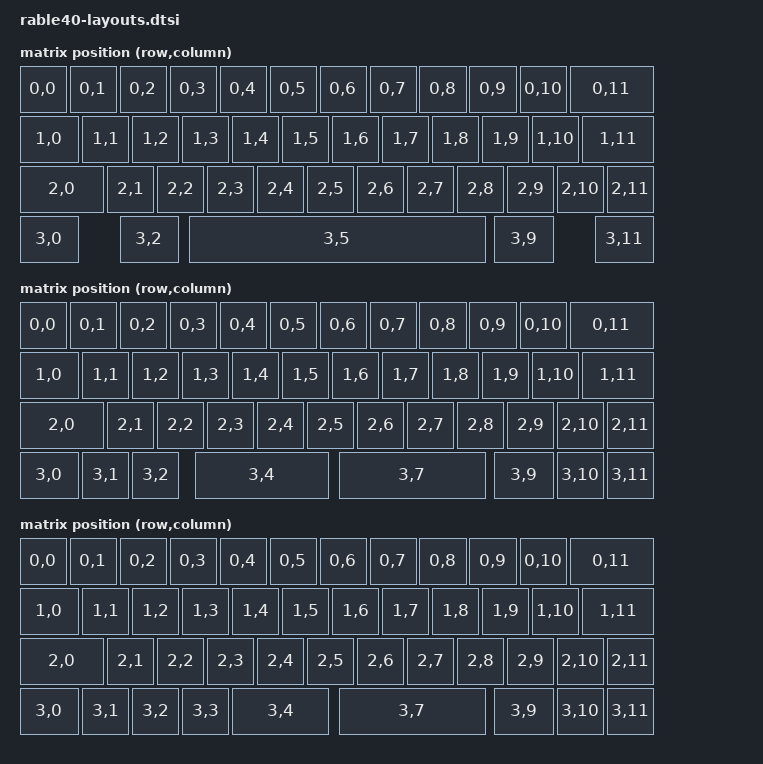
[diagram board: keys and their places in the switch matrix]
/* SPDX-License-Identifier: MIT */
/* Physical bottom-row presets; wiring verified against the supplied Gerbers. */
/ {
    space6_layout: space6_layout {
        compatible = "zmk,physical-layout";
        display-name = "6u spacebar (centered / off-center stem)";
        kscan = <&kscan0>;
        transform = <&space6_transform>;
        keys =
            <&key_physical_attrs 100 100 0 0 0 0 0>,
            <&key_physical_attrs 100 100 100 0 0 0 0>,
            <&key_physical_attrs 100 100 200 0 0 0 0>,
            <&key_physical_attrs 100 100 300 0 0 0 0>,
            <&key_physical_attrs 100 100 400 0 0 0 0>,
            <&key_physical_attrs 100 100 500 0 0 0 0>,
            <&key_physical_attrs 100 100 600 0 0 0 0>,
            <&key_physical_attrs 100 100 700 0 0 0 0>,
            <&key_physical_attrs 100 100 800 0 0 0 0>,
            <&key_physical_attrs 100 100 900 0 0 0 0>,
            <&key_physical_attrs 100 100 1000 0 0 0 0>,
            <&key_physical_attrs 175 100 1100 0 0 0 0>,
            <&key_physical_attrs 125 100 0 100 0 0 0>,
            <&key_physical_attrs 100 100 125 100 0 0 0>,
            <&key_physical_attrs 100 100 225 100 0 0 0>,
            <&key_physical_attrs 100 100 325 100 0 0 0>,
            <&key_physical_attrs 100 100 425 100 0 0 0>,
            <&key_physical_attrs 100 100 525 100 0 0 0>,
            <&key_physical_attrs 100 100 625 100 0 0 0>,
            <&key_physical_attrs 100 100 725 100 0 0 0>,
            <&key_physical_attrs 100 100 825 100 0 0 0>,
            <&key_physical_attrs 100 100 925 100 0 0 0>,
            <&key_physical_attrs 100 100 1025 100 0 0 0>,
            <&key_physical_attrs 150 100 1125 100 0 0 0>,
            <&key_physical_attrs 175 100 0 200 0 0 0>,
            <&key_physical_attrs 100 100 175 200 0 0 0>,
            <&key_physical_attrs 100 100 275 200 0 0 0>,
            <&key_physical_attrs 100 100 375 200 0 0 0>,
            <&key_physical_attrs 100 100 475 200 0 0 0>,
            <&key_physical_attrs 100 100 575 200 0 0 0>,
            <&key_physical_attrs 100 100 675 200 0 0 0>,
            <&key_physical_attrs 100 100 775 200 0 0 0>,
            <&key_physical_attrs 100 100 875 200 0 0 0>,
            <&key_physical_attrs 100 100 975 200 0 0 0>,
            <&key_physical_attrs 100 100 1075 200 0 0 0>,
            <&key_physical_attrs 100 100 1175 200 0 0 0>,
            <&key_physical_attrs 125 100 0 300 0 0 0>,
            <&key_physical_attrs 125 100 200 300 0 0 0>,
            <&key_physical_attrs 600 100 338 300 0 0 0>,
            <&key_physical_attrs 125 100 950 300 0 0 0>,
            <&key_physical_attrs 125 100 1150 300 0 0 0>;
    };
    space6_transform: space6_transform {
        compatible = "zmk,matrix-transform";
        rows = <4>;
        columns = <12>;
        map = <RC(0,0) RC(0,1) RC(0,2) RC(0,3) RC(0,4) RC(0,5) RC(0,6) RC(0,7) RC(0,8) RC(0,9) RC(0,10) RC(0,11) RC(1,0) RC(1,1) RC(1,2) RC(1,3) RC(1,4) RC(1,5) RC(1,6) RC(1,7) RC(1,8) RC(1,9) RC(1,10) RC(1,11) RC(2,0) RC(2,1) RC(2,2) RC(2,3) RC(2,4) RC(2,5) RC(2,6) RC(2,7) RC(2,8) RC(2,9) RC(2,10) RC(2,11) RC(3,0) RC(3,2) RC(3,5) RC(3,9) RC(3,11)>;
    };
    split275_3_layout: split275_3_layout {
        compatible = "zmk,physical-layout";
        display-name = "Split 2.75u + 3u (8 bottom keys)";
        kscan = <&kscan0>;
        transform = <&split275_3_transform>;
        keys =
            <&key_physical_attrs 100 100 0 0 0 0 0>,
            <&key_physical_attrs 100 100 100 0 0 0 0>,
            <&key_physical_attrs 100 100 200 0 0 0 0>,
            <&key_physical_attrs 100 100 300 0 0 0 0>,
            <&key_physical_attrs 100 100 400 0 0 0 0>,
            <&key_physical_attrs 100 100 500 0 0 0 0>,
            <&key_physical_attrs 100 100 600 0 0 0 0>,
            <&key_physical_attrs 100 100 700 0 0 0 0>,
            <&key_physical_attrs 100 100 800 0 0 0 0>,
            <&key_physical_attrs 100 100 900 0 0 0 0>,
            <&key_physical_attrs 100 100 1000 0 0 0 0>,
            <&key_physical_attrs 175 100 1100 0 0 0 0>,
            <&key_physical_attrs 125 100 0 100 0 0 0>,
            <&key_physical_attrs 100 100 125 100 0 0 0>,
            <&key_physical_attrs 100 100 225 100 0 0 0>,
            <&key_physical_attrs 100 100 325 100 0 0 0>,
            <&key_physical_attrs 100 100 425 100 0 0 0>,
            <&key_physical_attrs 100 100 525 100 0 0 0>,
            <&key_physical_attrs 100 100 625 100 0 0 0>,
            <&key_physical_attrs 100 100 725 100 0 0 0>,
            <&key_physical_attrs 100 100 825 100 0 0 0>,
            <&key_physical_attrs 100 100 925 100 0 0 0>,
            <&key_physical_attrs 100 100 1025 100 0 0 0>,
            <&key_physical_attrs 150 100 1125 100 0 0 0>,
            <&key_physical_attrs 175 100 0 200 0 0 0>,
            <&key_physical_attrs 100 100 175 200 0 0 0>,
            <&key_physical_attrs 100 100 275 200 0 0 0>,
            <&key_physical_attrs 100 100 375 200 0 0 0>,
            <&key_physical_attrs 100 100 475 200 0 0 0>,
            <&key_physical_attrs 100 100 575 200 0 0 0>,
            <&key_physical_attrs 100 100 675 200 0 0 0>,
            <&key_physical_attrs 100 100 775 200 0 0 0>,
            <&key_physical_attrs 100 100 875 200 0 0 0>,
            <&key_physical_attrs 100 100 975 200 0 0 0>,
            <&key_physical_attrs 100 100 1075 200 0 0 0>,
            <&key_physical_attrs 100 100 1175 200 0 0 0>,
            <&key_physical_attrs 125 100 0 300 0 0 0>,
            <&key_physical_attrs 100 100 125 300 0 0 0>,
            <&key_physical_attrs 100 100 225 300 0 0 0>,
            <&key_physical_attrs 275 100 350 300 0 0 0>,
            <&key_physical_attrs 300 100 638 300 0 0 0>,
            <&key_physical_attrs 125 100 950 300 0 0 0>,
            <&key_physical_attrs 100 100 1075 300 0 0 0>,
            <&key_physical_attrs 100 100 1175 300 0 0 0>;
    };
    split275_3_transform: split275_3_transform {
        compatible = "zmk,matrix-transform";
        rows = <4>;
        columns = <12>;
        map = <RC(0,0) RC(0,1) RC(0,2) RC(0,3) RC(0,4) RC(0,5) RC(0,6) RC(0,7) RC(0,8) RC(0,9) RC(0,10) RC(0,11) RC(1,0) RC(1,1) RC(1,2) RC(1,3) RC(1,4) RC(1,5) RC(1,6) RC(1,7) RC(1,8) RC(1,9) RC(1,10) RC(1,11) RC(2,0) RC(2,1) RC(2,2) RC(2,3) RC(2,4) RC(2,5) RC(2,6) RC(2,7) RC(2,8) RC(2,9) RC(2,10) RC(2,11) RC(3,0) RC(3,1) RC(3,2) RC(3,4) RC(3,7) RC(3,9) RC(3,10) RC(3,11)>;
    };
    split2_3_layout: split2_3_layout {
        compatible = "zmk,physical-layout";
        display-name = "Split 2u + 3u (9 bottom keys)";
        kscan = <&kscan0>;
        transform = <&split2_3_transform>;
        keys =
            <&key_physical_attrs 100 100 0 0 0 0 0>,
            <&key_physical_attrs 100 100 100 0 0 0 0>,
            <&key_physical_attrs 100 100 200 0 0 0 0>,
            <&key_physical_attrs 100 100 300 0 0 0 0>,
            <&key_physical_attrs 100 100 400 0 0 0 0>,
            <&key_physical_attrs 100 100 500 0 0 0 0>,
            <&key_physical_attrs 100 100 600 0 0 0 0>,
            <&key_physical_attrs 100 100 700 0 0 0 0>,
            <&key_physical_attrs 100 100 800 0 0 0 0>,
            <&key_physical_attrs 100 100 900 0 0 0 0>,
            <&key_physical_attrs 100 100 1000 0 0 0 0>,
            <&key_physical_attrs 175 100 1100 0 0 0 0>,
            <&key_physical_attrs 125 100 0 100 0 0 0>,
            <&key_physical_attrs 100 100 125 100 0 0 0>,
            <&key_physical_attrs 100 100 225 100 0 0 0>,
            <&key_physical_attrs 100 100 325 100 0 0 0>,
            <&key_physical_attrs 100 100 425 100 0 0 0>,
            <&key_physical_attrs 100 100 525 100 0 0 0>,
            <&key_physical_attrs 100 100 625 100 0 0 0>,
            <&key_physical_attrs 100 100 725 100 0 0 0>,
            <&key_physical_attrs 100 100 825 100 0 0 0>,
            <&key_physical_attrs 100 100 925 100 0 0 0>,
            <&key_physical_attrs 100 100 1025 100 0 0 0>,
            <&key_physical_attrs 150 100 1125 100 0 0 0>,
            <&key_physical_attrs 175 100 0 200 0 0 0>,
            <&key_physical_attrs 100 100 175 200 0 0 0>,
            <&key_physical_attrs 100 100 275 200 0 0 0>,
            <&key_physical_attrs 100 100 375 200 0 0 0>,
            <&key_physical_attrs 100 100 475 200 0 0 0>,
            <&key_physical_attrs 100 100 575 200 0 0 0>,
            <&key_physical_attrs 100 100 675 200 0 0 0>,
            <&key_physical_attrs 100 100 775 200 0 0 0>,
            <&key_physical_attrs 100 100 875 200 0 0 0>,
            <&key_physical_attrs 100 100 975 200 0 0 0>,
            <&key_physical_attrs 100 100 1075 200 0 0 0>,
            <&key_physical_attrs 100 100 1175 200 0 0 0>,
            <&key_physical_attrs 125 100 0 300 0 0 0>,
            <&key_physical_attrs 100 100 125 300 0 0 0>,
            <&key_physical_attrs 100 100 225 300 0 0 0>,
            <&key_physical_attrs 100 100 325 300 0 0 0>,
            <&key_physical_attrs 200 100 425 300 0 0 0>,
            <&key_physical_attrs 300 100 638 300 0 0 0>,
            <&key_physical_attrs 125 100 950 300 0 0 0>,
            <&key_physical_attrs 100 100 1075 300 0 0 0>,
            <&key_physical_attrs 100 100 1175 300 0 0 0>;
    };
    split2_3_transform: split2_3_transform {
        compatible = "zmk,matrix-transform";
        rows = <4>;
        columns = <12>;
        map = <RC(0,0) RC(0,1) RC(0,2) RC(0,3) RC(0,4) RC(0,5) RC(0,6) RC(0,7) RC(0,8) RC(0,9) RC(0,10) RC(0,11) RC(1,0) RC(1,1) RC(1,2) RC(1,3) RC(1,4) RC(1,5) RC(1,6) RC(1,7) RC(1,8) RC(1,9) RC(1,10) RC(1,11) RC(2,0) RC(2,1) RC(2,2) RC(2,3) RC(2,4) RC(2,5) RC(2,6) RC(2,7) RC(2,8) RC(2,9) RC(2,10) RC(2,11) RC(3,0) RC(3,1) RC(3,2) RC(3,3) RC(3,4) RC(3,7) RC(3,9) RC(3,10) RC(3,11)>;
    };
    split275_225_layout: split275_225_layout {
        compatible = "zmk,physical-layout";
        display-name = "Split 2.75u + 2.25u (9 bottom keys)";
        kscan = <&kscan0>;
        transform = <&split275_225_transform>;
        keys =
            <&key_physical_attrs 100 100 0 0 0 0 0>,
            <&key_physical_attrs 100 100 100 0 0 0 0>,
            <&key_physical_attrs 100 100 200 0 0 0 0>,
            <&key_physical_attrs 100 100 300 0 0 0 0>,
            <&key_physical_attrs 100 100 400 0 0 0 0>,
            <&key_physical_attrs 100 100 500 0 0 0 0>,
            <&key_physical_attrs 100 100 600 0 0 0 0>,
            <&key_physical_attrs 100 100 700 0 0 0 0>,
            <&key_physical_attrs 100 100 800 0 0 0 0>,
            <&key_physical_attrs 100 100 900 0 0 0 0>,
            <&key_physical_attrs 100 100 1000 0 0 0 0>,
            <&key_physical_attrs 175 100 1100 0 0 0 0>,
            <&key_physical_attrs 125 100 0 100 0 0 0>,
            <&key_physical_attrs 100 100 125 100 0 0 0>,
            <&key_physical_attrs 100 100 225 100 0 0 0>,
            <&key_physical_attrs 100 100 325 100 0 0 0>,
            <&key_physical_attrs 100 100 425 100 0 0 0>,
            <&key_physical_attrs 100 100 525 100 0 0 0>,
            <&key_physical_attrs 100 100 625 100 0 0 0>,
            <&key_physical_attrs 100 100 725 100 0 0 0>,
            <&key_physical_attrs 100 100 825 100 0 0 0>,
            <&key_physical_attrs 100 100 925 100 0 0 0>,
            <&key_physical_attrs 100 100 1025 100 0 0 0>,
            <&key_physical_attrs 150 100 1125 100 0 0 0>,
            <&key_physical_attrs 175 100 0 200 0 0 0>,
            <&key_physical_attrs 100 100 175 200 0 0 0>,
            <&key_physical_attrs 100 100 275 200 0 0 0>,
            <&key_physical_attrs 100 100 375 200 0 0 0>,
            <&key_physical_attrs 100 100 475 200 0 0 0>,
            <&key_physical_attrs 100 100 575 200 0 0 0>,
            <&key_physical_attrs 100 100 675 200 0 0 0>,
            <&key_physical_attrs 100 100 775 200 0 0 0>,
            <&key_physical_attrs 100 100 875 200 0 0 0>,
            <&key_physical_attrs 100 100 975 200 0 0 0>,
            <&key_physical_attrs 100 100 1075 200 0 0 0>,
            <&key_physical_attrs 100 100 1175 200 0 0 0>,
            <&key_physical_attrs 125 100 0 300 0 0 0>,
            <&key_physical_attrs 100 100 125 300 0 0 0>,
            <&key_physical_attrs 100 100 225 300 0 0 0>,
            <&key_physical_attrs 275 100 350 300 0 0 0>,
            <&key_physical_attrs 225 100 625 300 0 0 0>,
            <&key_physical_attrs 125 100 850 300 0 0 0>,
            <&key_physical_attrs 100 100 975 300 0 0 0>,
            <&key_physical_attrs 100 100 1075 300 0 0 0>,
            <&key_physical_attrs 100 100 1175 300 0 0 0>;
    };
    split275_225_transform: split275_225_transform {
        compatible = "zmk,matrix-transform";
        rows = <4>;
        columns = <12>;
        map = <RC(0,0) RC(0,1) RC(0,2) RC(0,3) RC(0,4) RC(0,5) RC(0,6) RC(0,7) RC(0,8) RC(0,9) RC(0,10) RC(0,11) RC(1,0) RC(1,1) RC(1,2) RC(1,3) RC(1,4) RC(1,5) RC(1,6) RC(1,7) RC(1,8) RC(1,9) RC(1,10) RC(1,11) RC(2,0) RC(2,1) RC(2,2) RC(2,3) RC(2,4) RC(2,5) RC(2,6) RC(2,7) RC(2,8) RC(2,9) RC(2,10) RC(2,11) RC(3,0) RC(3,1) RC(3,2) RC(3,4) RC(3,6) RC(3,8) RC(3,9) RC(3,10) RC(3,11)>;
    };
    split2_225_layout: split2_225_layout {
        compatible = "zmk,physical-layout";
        display-name = "Split 2u + 2.25u (10 bottom keys)";
        kscan = <&kscan0>;
        transform = <&split2_225_transform>;
        keys =
            <&key_physical_attrs 100 100 0 0 0 0 0>,
            <&key_physical_attrs 100 100 100 0 0 0 0>,
            <&key_physical_attrs 100 100 200 0 0 0 0>,
            <&key_physical_attrs 100 100 300 0 0 0 0>,
            <&key_physical_attrs 100 100 400 0 0 0 0>,
            <&key_physical_attrs 100 100 500 0 0 0 0>,
            <&key_physical_attrs 100 100 600 0 0 0 0>,
            <&key_physical_attrs 100 100 700 0 0 0 0>,
            <&key_physical_attrs 100 100 800 0 0 0 0>,
            <&key_physical_attrs 100 100 900 0 0 0 0>,
            <&key_physical_attrs 100 100 1000 0 0 0 0>,
            <&key_physical_attrs 175 100 1100 0 0 0 0>,
            <&key_physical_attrs 125 100 0 100 0 0 0>,
            <&key_physical_attrs 100 100 125 100 0 0 0>,
            <&key_physical_attrs 100 100 225 100 0 0 0>,
            <&key_physical_attrs 100 100 325 100 0 0 0>,
            <&key_physical_attrs 100 100 425 100 0 0 0>,
            <&key_physical_attrs 100 100 525 100 0 0 0>,
            <&key_physical_attrs 100 100 625 100 0 0 0>,
            <&key_physical_attrs 100 100 725 100 0 0 0>,
            <&key_physical_attrs 100 100 825 100 0 0 0>,
            <&key_physical_attrs 100 100 925 100 0 0 0>,
            <&key_physical_attrs 100 100 1025 100 0 0 0>,
            <&key_physical_attrs 150 100 1125 100 0 0 0>,
            <&key_physical_attrs 175 100 0 200 0 0 0>,
            <&key_physical_attrs 100 100 175 200 0 0 0>,
            <&key_physical_attrs 100 100 275 200 0 0 0>,
            <&key_physical_attrs 100 100 375 200 0 0 0>,
            <&key_physical_attrs 100 100 475 200 0 0 0>,
            <&key_physical_attrs 100 100 575 200 0 0 0>,
            <&key_physical_attrs 100 100 675 200 0 0 0>,
            <&key_physical_attrs 100 100 775 200 0 0 0>,
            <&key_physical_attrs 100 100 875 200 0 0 0>,
            <&key_physical_attrs 100 100 975 200 0 0 0>,
            <&key_physical_attrs 100 100 1075 200 0 0 0>,
            <&key_physical_attrs 100 100 1175 200 0 0 0>,
            <&key_physical_attrs 125 100 0 300 0 0 0>,
            <&key_physical_attrs 100 100 125 300 0 0 0>,
            <&key_physical_attrs 100 100 225 300 0 0 0>,
            <&key_physical_attrs 100 100 325 300 0 0 0>,
            <&key_physical_attrs 200 100 425 300 0 0 0>,
            <&key_physical_attrs 225 100 625 300 0 0 0>,
            <&key_physical_attrs 125 100 850 300 0 0 0>,
            <&key_physical_attrs 100 100 975 300 0 0 0>,
            <&key_physical_attrs 100 100 1075 300 0 0 0>,
            <&key_physical_attrs 100 100 1175 300 0 0 0>;
    };
    split2_225_transform: split2_225_transform {
        compatible = "zmk,matrix-transform";
        rows = <4>;
        columns = <12>;
        map = <RC(0,0) RC(0,1) RC(0,2) RC(0,3) RC(0,4) RC(0,5) RC(0,6) RC(0,7) RC(0,8) RC(0,9) RC(0,10) RC(0,11) RC(1,0) RC(1,1) RC(1,2) RC(1,3) RC(1,4) RC(1,5) RC(1,6) RC(1,7) RC(1,8) RC(1,9) RC(1,10) RC(1,11) RC(2,0) RC(2,1) RC(2,2) RC(2,3) RC(2,4) RC(2,5) RC(2,6) RC(2,7) RC(2,8) RC(2,9) RC(2,10) RC(2,11) RC(3,0) RC(3,1) RC(3,2) RC(3,3) RC(3,4) RC(3,6) RC(3,8) RC(3,9) RC(3,10) RC(3,11)>;
    };
    split3_3_layout: split3_3_layout {
        compatible = "zmk,physical-layout";
        display-name = "Split 3u + 3u (8 bottom keys)";
        kscan = <&kscan0>;
        transform = <&split3_3_transform>;
        keys =
            <&key_physical_attrs 100 100 0 0 0 0 0>,
            <&key_physical_attrs 100 100 100 0 0 0 0>,
            <&key_physical_attrs 100 100 200 0 0 0 0>,
            <&key_physical_attrs 100 100 300 0 0 0 0>,
            <&key_physical_attrs 100 100 400 0 0 0 0>,
            <&key_physical_attrs 100 100 500 0 0 0 0>,
            <&key_physical_attrs 100 100 600 0 0 0 0>,
            <&key_physical_attrs 100 100 700 0 0 0 0>,
            <&key_physical_attrs 100 100 800 0 0 0 0>,
            <&key_physical_attrs 100 100 900 0 0 0 0>,
            <&key_physical_attrs 100 100 1000 0 0 0 0>,
            <&key_physical_attrs 175 100 1100 0 0 0 0>,
            <&key_physical_attrs 125 100 0 100 0 0 0>,
            <&key_physical_attrs 100 100 125 100 0 0 0>,
            <&key_physical_attrs 100 100 225 100 0 0 0>,
            <&key_physical_attrs 100 100 325 100 0 0 0>,
            <&key_physical_attrs 100 100 425 100 0 0 0>,
            <&key_physical_attrs 100 100 525 100 0 0 0>,
            <&key_physical_attrs 100 100 625 100 0 0 0>,
            <&key_physical_attrs 100 100 725 100 0 0 0>,
            <&key_physical_attrs 100 100 825 100 0 0 0>,
            <&key_physical_attrs 100 100 925 100 0 0 0>,
            <&key_physical_attrs 100 100 1025 100 0 0 0>,
            <&key_physical_attrs 150 100 1125 100 0 0 0>,
            <&key_physical_attrs 175 100 0 200 0 0 0>,
            <&key_physical_attrs 100 100 175 200 0 0 0>,
            <&key_physical_attrs 100 100 275 200 0 0 0>,
            <&key_physical_attrs 100 100 375 200 0 0 0>,
            <&key_physical_attrs 100 100 475 200 0 0 0>,
            <&key_physical_attrs 100 100 575 200 0 0 0>,
            <&key_physical_attrs 100 100 675 200 0 0 0>,
            <&key_physical_attrs 100 100 775 200 0 0 0>,
            <&key_physical_attrs 100 100 875 200 0 0 0>,
            <&key_physical_attrs 100 100 975 200 0 0 0>,
            <&key_physical_attrs 100 100 1075 200 0 0 0>,
            <&key_physical_attrs 100 100 1175 200 0 0 0>,
            <&key_physical_attrs 125 100 0 300 0 0 0>,
            <&key_physical_attrs 100 100 125 300 0 0 0>,
            <&key_physical_attrs 100 100 225 300 0 0 0>,
            <&key_physical_attrs 300 100 338 300 0 0 0>,
            <&key_physical_attrs 300 100 638 300 0 0 0>,
            <&key_physical_attrs 125 100 950 300 0 0 0>,
            <&key_physical_attrs 100 100 1075 300 0 0 0>,
            <&key_physical_attrs 100 100 1175 300 0 0 0>;
    };
    split3_3_transform: split3_3_transform {
        compatible = "zmk,matrix-transform";
        rows = <4>;
        columns = <12>;
        map = <RC(0,0) RC(0,1) RC(0,2) RC(0,3) RC(0,4) RC(0,5) RC(0,6) RC(0,7) RC(0,8) RC(0,9) RC(0,10) RC(0,11) RC(1,0) RC(1,1) RC(1,2) RC(1,3) RC(1,4) RC(1,5) RC(1,6) RC(1,7) RC(1,8) RC(1,9) RC(1,10) RC(1,11) RC(2,0) RC(2,1) RC(2,2) RC(2,3) RC(2,4) RC(2,5) RC(2,6) RC(2,7) RC(2,8) RC(2,9) RC(2,10) RC(2,11) RC(3,0) RC(3,1) RC(3,2) RC(3,4) RC(3,7) RC(3,9) RC(3,10) RC(3,11)>;
    };
};
&rable40_position_map {
    space6 {
        physical-layout = <&space6_layout>;
        positions = <0 1 2 3 4 5 6 7 8 9 10 11 12 13 14 15 16 17 18 19 20 21 22 23 24 25 26 27 28 29 30 31 32 33 34 35 36 37 38 39 40 41 42 43 44 45 46 47>;
    };
    split275_3 {
        physical-layout = <&split275_3_layout>;
        positions = <0 1 2 3 4 5 6 7 8 9 10 11 12 13 14 15 16 17 18 19 20 21 22 23 24 25 26 27 28 29 30 31 32 33 34 35 36 38 44 41 43 37 45 39 46 40 47 42>;
    };
    split2_3 {
        physical-layout = <&split2_3_layout>;
        positions = <0 1 2 3 4 5 6 7 8 9 10 11 12 13 14 15 16 17 18 19 20 21 22 23 24 25 26 27 28 29 30 31 32 33 34 35 36 38 45 42 44 37 39 40 46 41 47 43>;
    };
    split275_225 {
        physical-layout = <&split275_225_layout>;
        positions = <0 1 2 3 4 5 6 7 8 9 10 11 12 13 14 15 16 17 18 19 20 21 22 23 24 25 26 27 28 29 30 31 32 33 34 35 36 38 45 42 44 37 46 39 40 47 41 43>;
    };
    split2_225 {
        physical-layout = <&split2_225_layout>;
        positions = <0 1 2 3 4 5 6 7 8 9 10 11 12 13 14 15 16 17 18 19 20 21 22 23 24 25 26 27 28 29 30 31 32 33 34 35 36 38 46 43 45 37 39 40 41 47 42 44>;
    };
    split3_3 {
        physical-layout = <&split3_3_layout>;
        positions = <0 1 2 3 4 5 6 7 8 9 10 11 12 13 14 15 16 17 18 19 20 21 22 23 24 25 26 27 28 29 30 31 32 33 34 35 36 38 44 41 43 37 45 39 46 40 47 42>;
    };
};
